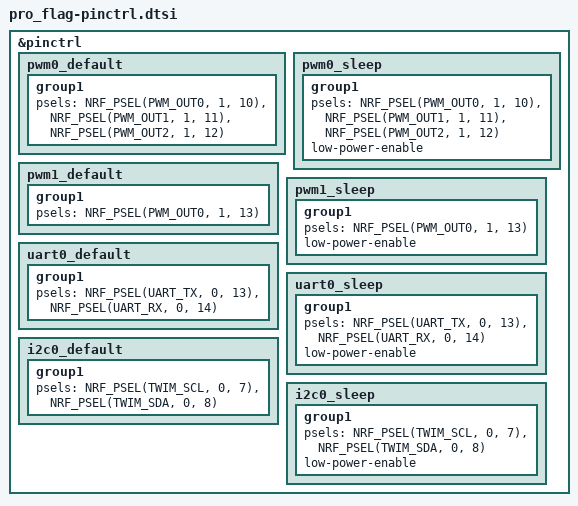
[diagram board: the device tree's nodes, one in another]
&pinctrl {
    pwm0_default: pwm0_default {
        group1 {
            psels = <NRF_PSEL(PWM_OUT0, 1, 10)>,
                    <NRF_PSEL(PWM_OUT1, 1, 11)>,
                    <NRF_PSEL(PWM_OUT2, 1, 12)>;
        };
    };

    pwm0_sleep: pwm0_sleep {
        group1 {
            psels = <NRF_PSEL(PWM_OUT0, 1, 10)>,
                    <NRF_PSEL(PWM_OUT1, 1, 11)>,
                    <NRF_PSEL(PWM_OUT2, 1, 12)>;
                    low-power-enable;
        };
    };

    pwm1_default: pwm1_default {
        group1 {
            psels = <NRF_PSEL(PWM_OUT0, 1, 13)>;
        };
    };

    pwm1_sleep: pwm1_sleep {
        group1 {
            psels = <NRF_PSEL(PWM_OUT0, 1, 13)>;
            low-power-enable;
        };
    };

    uart0_default: uart0_default {
        group1 {
            psels = <NRF_PSEL(UART_TX, 0, 13)>, <NRF_PSEL(UART_RX, 0, 14)>;
        };
    };

    uart0_sleep: uart0_sleep {
        group1 {
            psels = <NRF_PSEL(UART_TX, 0, 13)>, <NRF_PSEL(UART_RX, 0, 14)>;
            low-power-enable;
        };
    };

    i2c0_default: i2c0_default {
        group1 {
            psels = <NRF_PSEL(TWIM_SCL, 0, 7)>, <NRF_PSEL(TWIM_SDA, 0, 8)>;
        };
    };

    i2c0_sleep: i2c0_sleep {
        group1 {
            psels = <NRF_PSEL(TWIM_SCL, 0, 7)>, <NRF_PSEL(TWIM_SDA, 0, 8)>;
            low-power-enable;
        };
    };
};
